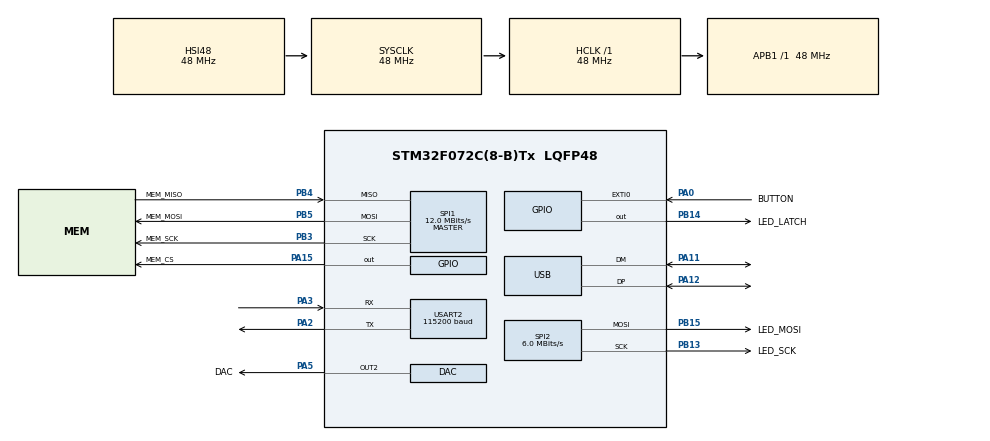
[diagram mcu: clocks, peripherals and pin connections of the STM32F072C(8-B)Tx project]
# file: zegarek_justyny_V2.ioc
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DAC.DAC_Trigger2=DAC_TRIGGER_T6_TRGO
DAC.WaveGeneration2=DISABLE
Dma.DAC_CH2.1.Direction=DMA_MEMORY_TO_PERIPH
Dma.DAC_CH2.1.Instance=DMA1_Channel4
Dma.DAC_CH2.1.MemDataAlignment=DMA_MDATAALIGN_HALFWORD
Dma.DAC_CH2.1.MemInc=DMA_MINC_ENABLE
Dma.DAC_CH2.1.Mode=DMA_CIRCULAR
Dma.DAC_CH2.1.PeriphDataAlignment=DMA_PDATAALIGN_HALFWORD
Dma.DAC_CH2.1.PeriphInc=DMA_PINC_DISABLE
Dma.DAC_CH2.1.Priority=DMA_PRIORITY_VERY_HIGH
Dma.Request0=USART2_RX
Dma.Request1=DAC_CH2
Dma.USART2_RX.0.Direction=DMA_PERIPH_TO_MEMORY
Dma.USART2_RX.0.Instance=DMA1_Channel6
Dma.USART2_RX.0.MemDataAlignment=DMA_MDATAALIGN_BYTE
Dma.USART2_RX.0.MemInc=DMA_MINC_ENABLE
Dma.USART2_RX.0.Mode=DMA_NORMAL
Dma.USART2_RX.0.PeriphDataAlignment=DMA_PDATAALIGN_BYTE
Dma.USART2_RX.0.PeriphInc=DMA_PINC_DISABLE
Dma.USART2_RX.0.Priority=DMA_PRIORITY_HIGH
FATFS._FS_MINIMIZE=1
FATFS._FS_NORTC=1
FATFS._FS_RPATH=1
FATFS._FS_TINY=1
FATFS._MAX_SS=4096
FATFS._MIN_SS=4096
FATFS._NORTC_MDAY=3
FATFS._NORTC_MON=8
FATFS._NORTC_YEAR=1997
FATFS._USE_STRFUNC=1
Mcu.Family=STM32F0
Mcu.Name=STM32F072C(8-B)Tx
Mcu.Package=LQFP48
NVIC.DMA1_Channel4_5_6_7_IRQn=true\:0\:0\:false\:false\:true\:false
NVIC.EXTI0_1_IRQn=true\:0\:0\:false\:false\:true\:true
NVIC.TIM7_IRQn=true\:1\:0\:true\:false\:true\:true
NVIC.USB_IRQn=true\:0\:0\:false\:false\:true\:true
PA0.GPIO_Label=BUTTON
PA0.GPIO_ModeDefaultEXTI=GPIO_MODE_IT_FALLING
PA0.GPIO_PuPd=GPIO_PULLUP
PA0.Signal=GPXTI0
PA11.Mode=Device
PA11.Signal=USB_DM
PA12.Mode=Device
PA12.Signal=USB_DP
PA13.Mode=Serial_Wire
PA13.Signal=SYS_SWDIO
PA14.Mode=Serial_Wire
PA14.Signal=SYS_SWCLK
PA15.GPIO_Label=MEM_CS
PA15.GPIO_Speed=GPIO_SPEED_FREQ_HIGH
PA15.PinState=GPIO_PIN_SET
PA15.Signal=GPIO_Output
PA2.Mode=Asynchronous
PA2.Signal=USART2_TX
PA3.Mode=Asynchronous
PA3.Signal=USART2_RX
PA5.GPIO_Label=DAC
PA5.Signal=COMP_DAC2_group
PB13.GPIO_Label=LED_SCK
PB13.Mode=TX_Only_Simplex_Unidirect_Master
PB13.Signal=SPI2_SCK
PB14.GPIO_Label=LED_LATCH
PB14.Signal=GPIO_Output
PB15.GPIO_Label=LED_MOSI
PB15.Mode=TX_Only_Simplex_Unidirect_Master
PB15.Signal=SPI2_MOSI
PB3.GPIO_Label=MEM_SCK
PB3.Mode=Full_Duplex_Master
PB3.Signal=SPI1_SCK
PB4.GPIO_Label=MEM_MISO
PB4.Mode=Full_Duplex_Master
PB4.Signal=SPI1_MISO
PB5.GPIO_Label=MEM_MOSI
PB5.Mode=Full_Duplex_Master
PB5.Signal=SPI1_MOSI
ProjectManager.HeapSize=0x200
ProjectManager.StackSize=0x400
ProjectManager.TargetToolchain=SW4STM32
RCC.AHBFreq_Value=48000000
RCC.APB1Freq_Value=48000000
RCC.APB1TimFreq_Value=48000000
RCC.HCLKFreq_Value=48000000
RCC.SYSCLKFreq_VALUE=48000000
RCC.SYSCLKSource=RCC_SYSCLKSOURCE_HSI48
RTC.Alarm-Alarm\ A=RTC_ALARM_A
RTC.Format=RTC_FORMAT_BIN
RTC.SynchPrediv=318
SH.COMP_DAC2_group.0=DAC_OUT2,DAC_OUT2
SPI1.BaudRatePrescaler=SPI_BAUDRATEPRESCALER_4
SPI1.CLKPhase=SPI_PHASE_2EDGE
SPI1.CLKPolarity=SPI_POLARITY_HIGH
SPI1.CalculateBaudRate=12.0 MBits/s
SPI1.DataSize=SPI_DATASIZE_8BIT
SPI1.Direction=SPI_DIRECTION_2LINES
SPI1.Mode=SPI_MODE_MASTER
SPI1.VirtualType=VM_MASTER
SPI2.BaudRatePrescaler=SPI_BAUDRATEPRESCALER_8
SPI2.CLKPhase=SPI_PHASE_2EDGE
SPI2.CLKPolarity=SPI_POLARITY_HIGH
SPI2.CalculateBaudRate=6.0 MBits/s
SPI2.DataSize=SPI_DATASIZE_8BIT
SPI2.Direction=SPI_DIRECTION_2LINES
SPI2.Mode=SPI_MODE_MASTER
SPI2.VirtualType=VM_MASTER
TIM6.Period=32768
TIM6.TIM_MasterOutputTrigger=TIM_TRGO_UPDATE
TIM7.Period=210
TIM7.Prescaler=1000
USART2.BaudRate=115200
USART2.VirtualMode-Asynchronous=VM_ASYNC
USART2.WordLength=WORDLENGTH_8B
USB_DEVICE.CLASS_NAME_FS=MSC
USB_DEVICE.MANUFACTURER_STRING=Robert Krauze
USB_DEVICE.MSC_MEDIA_PACKET=4096
USB_DEVICE.PRODUCT_STRING_MSC_FS=Zegarek
USB_DEVICE.VirtualMode=Msc
USB_DEVICE.VirtualModeFS=Msc_FS
VP_FATFS_VS_Generic.Mode=User_defined
VP_RTC_VS_RTC_Activate.Mode=RTC_Enabled
VP_RTC_VS_RTC_Alarm_A_Intern.Mode=Alarm A
VP_RTC_VS_RTC_Calendar.Mode=RTC_Calendar
VP_TIM6_VS_ClockSourceINT.Mode=Enable_Timer
VP_TIM7_VS_ClockSourceINT.Mode=Enable_Timer
VP_USB_DEVICE_VS_USB_DEVICE_MSC_FS.Mode=MSC_FS
board=zegarek_justyny_V2

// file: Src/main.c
/**
  ******************************************************************************
  * @file           : main.c
  * @brief          : Main program body
  ******************************************************************************
  * This notice applies to any and all portions of this file
  * that are not between comment pairs USER CODE BEGIN and
  * USER CODE END. Other portions of this file, whether
  * inserted by the user or by software development tools
  * are owned by their respective copyright owners.
  *
  * Copyright (c) 2018 STMicroelectronics International N.V.
  * All rights reserved.
  *
  * Redistribution and use in source and binary forms, with or without
  * modification, are permitted, provided that the following conditions are met:
  *
  * 1. Redistribution of source code must retain the above copyright notice,
  *    this list of conditions and the following disclaimer.
  * 2. Redistributions in binary form must reproduce the above copyright notice,
  *    this list of conditions and the following disclaimer in the documentation
  *    and/or other materials provided with the distribution.
  * 3. Neither the name of STMicroelectronics nor the names of other
  *    contributors to this software may be used to endorse or promote products
  *    derived from this software without specific written permission.
  * 4. This software, including modifications and/or derivative works of this
  *    software, must execute solely and exclusively on microcontroller or
  *    microprocessor devices manufactured by or for STMicroelectronics.
  * 5. Redistribution and use of this software other than as permitted under
  *    this license is void and will automatically terminate your rights under
  *    this license.
  *
  * THIS SOFTWARE IS PROVIDED BY STMICROELECTRONICS AND CONTRIBUTORS "AS IS"
  * AND ANY EXPRESS, IMPLIED OR STATUTORY WARRANTIES, INCLUDING, BUT NOT
  * LIMITED TO, THE IMPLIED WARRANTIES OF MERCHANTABILITY, FITNESS FOR A
  * PARTICULAR PURPOSE AND NON-INFRINGEMENT OF THIRD PARTY INTELLECTUAL PROPERTY
  * RIGHTS ARE DISCLAIMED TO THE FULLEST EXTENT PERMITTED BY LAW. IN NO EVENT
  * SHALL STMICROELECTRONICS OR CONTRIBUTORS BE LIABLE FOR ANY DIRECT, INDIRECT,
  * INCIDENTAL, SPECIAL, EXEMPLARY, OR CONSEQUENTIAL DAMAGES (INCLUDING, BUT NOT
  * LIMITED TO, PROCUREMENT OF SUBSTITUTE GOODS OR SERVICES; LOSS OF USE, DATA,
  * OR PROFITS; OR BUSINESS INTERRUPTION) HOWEVER CAUSED AND ON ANY THEORY OF
  * LIABILITY, WHETHER IN CONTRACT, STRICT LIABILITY, OR TORT (INCLUDING
  * NEGLIGENCE OR OTHERWISE) ARISING IN ANY WAY OUT OF THE USE OF THIS SOFTWARE,
  * EVEN IF ADVISED OF THE POSSIBILITY OF SUCH DAMAGE.
  *
  ******************************************************************************
  */
#include "main.h"
#include "stm32f0xx_hal.h"
#include "fatfs.h"
#include "usb_device.h"

/* USER CODE BEGIN Includes */
#include "../SW4STM32/zegarek_justyny_V2/Application/User/Led/led.h"
#include "../SW4STM32/zegarek_justyny_V2/Application/User/WiFi/wifi.h"
#include "../SW4STM32/zegarek_justyny_V2/Application/User/Flash_mem/mem_funs.h"
#include "../SW4STM32/zegarek_justyny_V2/Application/User/Scheduler/scheduler.h"
#include "../SW4STM32/zegarek_justyny_V2/Application/User/RTC/rtc.h"
#include "../SW4STM32/zegarek_justyny_V2/Application/User/WAV_player/wav_player.h"
#include "usbd_msc.h"
/* USER CODE END Includes */

DAC_HandleTypeDef hdac;
DMA_HandleTypeDef hdma_dac_ch2;

RTC_HandleTypeDef hrtc;

SPI_HandleTypeDef hspi1;
SPI_HandleTypeDef hspi2;

TIM_HandleTypeDef htim6;
TIM_HandleTypeDef htim7;

UART_HandleTypeDef huart2;
DMA_HandleTypeDef hdma_usart2_rx;

/* USER CODE BEGIN PV */
/* Private variables ---------------------------------------------------------*/
/* USER CODE END PV */

void SystemClock_Config(void);
static void MX_GPIO_Init(void);
static void MX_DMA_Init(void);
static void MX_DAC_Init(void);
static void MX_RTC_Init(void);
static void MX_SPI1_Init(void);
static void MX_SPI2_Init(void);
static void MX_USART2_UART_Init(void);
static void MX_TIM6_Init(void);
static void MX_TIM7_Init(void);

/* USER CODE BEGIN PFP */
/* Private function prototypes -----------------------------------------------*/

/* USER CODE END PFP */

/* USER CODE BEGIN 0 */
//Fiszera 00000111111
/* USER CODE END 0 */

int main(void)
{

  /* MCU Configuration----------------------------------------------------------*/

  /* Reset of all peripherals, Initializes the Flash interface and the Systick. */
  HAL_Init();

  /* Configure the system clock */
  SystemClock_Config();

  /* USER CODE BEGIN SysInit */
  HAL_Delay(1500);
  /* USER CODE END SysInit */

  /* Initialize all configured peripherals */
  MX_GPIO_Init();
  MX_DMA_Init();
  MX_DAC_Init();
  MX_RTC_Init();
  MX_SPI1_Init();
  MX_SPI2_Init();
  MX_USART2_UART_Init();
  MX_FATFS_Init();
  MX_TIM6_Init();
  MX_TIM7_Init();
  /* USER CODE BEGIN 2 */

#if 1
#if 0
  MX_USB_DEVICE_Init();

  	mem_register_SPI(&hspi1);
	mem_init();

#else
	mem_register_SPI(&hspi1);
	mem_init();

	f_forcemount(0);

	wifi_init(&huart2);
	rtc_module_init();

	led_init(&htim7, &hspi2, LED_LATCH_GPIO_Port, LED_LATCH_Pin);

#endif
#endif
  /* USER CODE END 2 */

  /* Infinite loop */
  while (1)
  {

  /* USER CODE BEGIN 3 */
	  scheduler_pool();
  }
  /* USER CODE END 3 */

}

void SystemClock_Config(void)
{

  RCC_OscInitTypeDef RCC_OscInitStruct;
  RCC_ClkInitTypeDef RCC_ClkInitStruct;
  RCC_PeriphCLKInitTypeDef PeriphClkInit;

    /**Initializes the CPU, AHB and APB busses clocks
    */
  RCC_OscInitStruct.OscillatorType = RCC_OSCILLATORTYPE_HSI48|RCC_OSCILLATORTYPE_LSI;
  RCC_OscInitStruct.HSI48State = RCC_HSI48_ON;
  RCC_OscInitStruct.LSIState = RCC_LSI_ON;
  RCC_OscInitStruct.PLL.PLLState = RCC_PLL_NONE;
  if (HAL_RCC_OscConfig(&RCC_OscInitStruct) != HAL_OK)
  {
    _Error_Handler(__FILE__, __LINE__);
  }

    /**Initializes the CPU, AHB and APB busses clocks
    */
  RCC_ClkInitStruct.ClockType = RCC_CLOCKTYPE_HCLK|RCC_CLOCKTYPE_SYSCLK
                              |RCC_CLOCKTYPE_PCLK1;
  RCC_ClkInitStruct.SYSCLKSource = RCC_SYSCLKSOURCE_HSI48;
  RCC_ClkInitStruct.AHBCLKDivider = RCC_SYSCLK_DIV1;
  RCC_ClkInitStruct.APB1CLKDivider = RCC_HCLK_DIV1;

  if (HAL_RCC_ClockConfig(&RCC_ClkInitStruct, FLASH_LATENCY_1) != HAL_OK)
  {
    _Error_Handler(__FILE__, __LINE__);
  }

  PeriphClkInit.PeriphClockSelection = RCC_PERIPHCLK_USB|RCC_PERIPHCLK_USART2
                              |RCC_PERIPHCLK_RTC;
  PeriphClkInit.Usart2ClockSelection = RCC_USART2CLKSOURCE_PCLK1;
  PeriphClkInit.RTCClockSelection = RCC_RTCCLKSOURCE_LSI;
  PeriphClkInit.UsbClockSelection = RCC_USBCLKSOURCE_HSI48;

  if (HAL_RCCEx_PeriphCLKConfig(&PeriphClkInit) != HAL_OK)
  {
    _Error_Handler(__FILE__, __LINE__);
  }

    /**Configure the Systick interrupt time
    */
  HAL_SYSTICK_Config(HAL_RCC_GetHCLKFreq()/1000);

    /**Configure the Systick
    */
  HAL_SYSTICK_CLKSourceConfig(SYSTICK_CLKSOURCE_HCLK);

  /* SysTick_IRQn interrupt configuration */
  HAL_NVIC_SetPriority(SysTick_IRQn, 0, 0);
}

/* DAC init function */
static void MX_DAC_Init(void)
{

  DAC_ChannelConfTypeDef sConfig;

    /**DAC Initialization
    */
  hdac.Instance = DAC;
  if (HAL_DAC_Init(&hdac) != HAL_OK)
  {
    _Error_Handler(__FILE__, __LINE__);
  }

    /**DAC channel OUT2 config
    */
  sConfig.DAC_Trigger = DAC_TRIGGER_T6_TRGO;
  sConfig.DAC_OutputBuffer = DAC_OUTPUTBUFFER_ENABLE;
  if (HAL_DAC_ConfigChannel(&hdac, &sConfig, DAC_CHANNEL_2) != HAL_OK)
  {
    _Error_Handler(__FILE__, __LINE__);
  }

}

/* RTC init function */
static void MX_RTC_Init(void)
{

  RTC_TimeTypeDef sTime;
  RTC_DateTypeDef sDate;
  RTC_AlarmTypeDef sAlarm;

    /**Initialize RTC Only
    */
  hrtc.Instance = RTC;
  hrtc.Init.HourFormat = RTC_HOURFORMAT_24;
  hrtc.Init.AsynchPrediv = 127;
  hrtc.Init.SynchPrediv = 318;
  hrtc.Init.OutPut = RTC_OUTPUT_DISABLE;
  hrtc.Init.OutPutPolarity = RTC_OUTPUT_POLARITY_HIGH;
  hrtc.Init.OutPutType = RTC_OUTPUT_TYPE_OPENDRAIN;
  if (HAL_RTC_Init(&hrtc) != HAL_OK)
  {
    _Error_Handler(__FILE__, __LINE__);
  }

    /**Initialize RTC and set the Time and Date
    */
  sTime.Hours = 0;
  sTime.Minutes = 0;
  sTime.Seconds = 0;
  sTime.DayLightSaving = RTC_DAYLIGHTSAVING_NONE;
  sTime.StoreOperation = RTC_STOREOPERATION_RESET;
  if (HAL_RTC_SetTime(&hrtc, &sTime, RTC_FORMAT_BIN) != HAL_OK)
  {
    _Error_Handler(__FILE__, __LINE__);
  }

  sDate.WeekDay = RTC_WEEKDAY_MONDAY;
  sDate.Month = RTC_MONTH_JANUARY;
  sDate.Date = 1;
  sDate.Year = 0;

  if (HAL_RTC_SetDate(&hrtc, &sDate, RTC_FORMAT_BIN) != HAL_OK)
  {
    _Error_Handler(__FILE__, __LINE__);
  }

    /**Enable the Alarm A
    */
  sAlarm.AlarmTime.Hours = 0;
  sAlarm.AlarmTime.Minutes = 0;
  sAlarm.AlarmTime.Seconds = 0;
  sAlarm.AlarmTime.SubSeconds = 0;
  sAlarm.AlarmTime.DayLightSaving = RTC_DAYLIGHTSAVING_NONE;
  sAlarm.AlarmTime.StoreOperation = RTC_STOREOPERATION_RESET;
  sAlarm.AlarmMask = RTC_ALARMMASK_NONE;
  sAlarm.AlarmSubSecondMask = RTC_ALARMSUBSECONDMASK_ALL;
  sAlarm.AlarmDateWeekDaySel = RTC_ALARMDATEWEEKDAYSEL_DATE;
  sAlarm.AlarmDateWeekDay = 1;
  sAlarm.Alarm = RTC_ALARM_A;
  if (HAL_RTC_SetAlarm(&hrtc, &sAlarm, RTC_FORMAT_BIN) != HAL_OK)
  {
    _Error_Handler(__FILE__, __LINE__);
  }

}

/* SPI1 init function */
static void MX_SPI1_Init(void)
{

  /* SPI1 parameter configuration*/
  hspi1.Instance = SPI1;
  hspi1.Init.Mode = SPI_MODE_MASTER;
  hspi1.Init.Direction = SPI_DIRECTION_2LINES;
  hspi1.Init.DataSize = SPI_DATASIZE_8BIT;
  hspi1.Init.CLKPolarity = SPI_POLARITY_HIGH;
  hspi1.Init.CLKPhase = SPI_PHASE_2EDGE;
  hspi1.Init.NSS = SPI_NSS_SOFT;
  hspi1.Init.BaudRatePrescaler = SPI_BAUDRATEPRESCALER_4;
  hspi1.Init.FirstBit = SPI_FIRSTBIT_MSB;
  hspi1.Init.TIMode = SPI_TIMODE_DISABLE;
  hspi1.Init.CRCCalculation = SPI_CRCCALCULATION_DISABLE;
  hspi1.Init.CRCPolynomial = 7;
  hspi1.Init.CRCLength = SPI_CRC_LENGTH_DATASIZE;
  hspi1.Init.NSSPMode = SPI_NSS_PULSE_DISABLE;
  if (HAL_SPI_Init(&hspi1) != HAL_OK)
  {
    _Error_Handler(__FILE__, __LINE__);
  }

}

/* SPI2 init function */
static void MX_SPI2_Init(void)
{

  /* SPI2 parameter configuration*/
  hspi2.Instance = SPI2;
  hspi2.Init.Mode = SPI_MODE_MASTER;
  hspi2.Init.Direction = SPI_DIRECTION_2LINES;
  hspi2.Init.DataSize = SPI_DATASIZE_8BIT;
  hspi2.Init.CLKPolarity = SPI_POLARITY_HIGH;
  hspi2.Init.CLKPhase = SPI_PHASE_2EDGE;
  hspi2.Init.NSS = SPI_NSS_SOFT;
  hspi2.Init.BaudRatePrescaler = SPI_BAUDRATEPRESCALER_8;
  hspi2.Init.FirstBit = SPI_FIRSTBIT_MSB;
  hspi2.Init.TIMode = SPI_TIMODE_DISABLE;
  hspi2.Init.CRCCalculation = SPI_CRCCALCULATION_DISABLE;
  hspi2.Init.CRCPolynomial = 7;
  hspi2.Init.CRCLength = SPI_CRC_LENGTH_DATASIZE;
  hspi2.Init.NSSPMode = SPI_NSS_PULSE_DISABLE;
  if (HAL_SPI_Init(&hspi2) != HAL_OK)
  {
    _Error_Handler(__FILE__, __LINE__);
  }

}

/* TIM6 init function */
static void MX_TIM6_Init(void)
{

  TIM_MasterConfigTypeDef sMasterConfig;

  htim6.Instance = TIM6;
  htim6.Init.Prescaler = 0;
  htim6.Init.CounterMode = TIM_COUNTERMODE_UP;
  htim6.Init.Period = 32768;
  htim6.Init.AutoReloadPreload = TIM_AUTORELOAD_PRELOAD_DISABLE;
  if (HAL_TIM_Base_Init(&htim6) != HAL_OK)
  {
    _Error_Handler(__FILE__, __LINE__);
  }

  sMasterConfig.MasterOutputTrigger = TIM_TRGO_UPDATE;
  sMasterConfig.MasterSlaveMode = TIM_MASTERSLAVEMODE_DISABLE;
  if (HAL_TIMEx_MasterConfigSynchronization(&htim6, &sMasterConfig) != HAL_OK)
  {
    _Error_Handler(__FILE__, __LINE__);
  }

}

/* TIM7 init function */
static void MX_TIM7_Init(void)
{

  TIM_MasterConfigTypeDef sMasterConfig;

  htim7.Instance = TIM7;
  htim7.Init.Prescaler = 1000;
  htim7.Init.CounterMode = TIM_COUNTERMODE_UP;
  htim7.Init.Period = 300;
  htim7.Init.AutoReloadPreload = TIM_AUTORELOAD_PRELOAD_DISABLE;
  if (HAL_TIM_Base_Init(&htim7) != HAL_OK)
  {
    _Error_Handler(__FILE__, __LINE__);
  }

  sMasterConfig.MasterOutputTrigger = TIM_TRGO_RESET;
  sMasterConfig.MasterSlaveMode = TIM_MASTERSLAVEMODE_DISABLE;
  if (HAL_TIMEx_MasterConfigSynchronization(&htim7, &sMasterConfig) != HAL_OK)
  {
    _Error_Handler(__FILE__, __LINE__);
  }

}

/* USART2 init function */
static void MX_USART2_UART_Init(void)
{

  huart2.Instance = USART2;
  huart2.Init.BaudRate = 115200;
  huart2.Init.WordLength = UART_WORDLENGTH_8B;
  huart2.Init.StopBits = UART_STOPBITS_1;
  huart2.Init.Parity = UART_PARITY_NONE;
  huart2.Init.Mode = UART_MODE_TX_RX;
  huart2.Init.HwFlowCtl = UART_HWCONTROL_NONE;
  huart2.Init.OverSampling = UART_OVERSAMPLING_16;
  huart2.Init.OneBitSampling = UART_ONE_BIT_SAMPLE_DISABLE;
  huart2.AdvancedInit.AdvFeatureInit = UART_ADVFEATURE_NO_INIT;
  if (HAL_UART_Init(&huart2) != HAL_OK)
  {
    _Error_Handler(__FILE__, __LINE__);
  }

}

static void MX_DMA_Init(void)
{
  /* DMA controller clock enable */
  __HAL_RCC_DMA1_CLK_ENABLE();

  /* DMA interrupt init */
  /* DMA1_Channel4_5_6_7_IRQn interrupt configuration */
  HAL_NVIC_SetPriority(DMA1_Channel4_5_6_7_IRQn, 0, 0);
  HAL_NVIC_EnableIRQ(DMA1_Channel4_5_6_7_IRQn);

}

/** Configure pins as
        * Analog
        * Input
        * Output
        * EVENT_OUT
        * EXTI
*/
static void MX_GPIO_Init(void)
{

  GPIO_InitTypeDef GPIO_InitStruct;

  /* GPIO Ports Clock Enable */
  __HAL_RCC_GPIOA_CLK_ENABLE();
  __HAL_RCC_GPIOB_CLK_ENABLE();

  /*Configure GPIO pin Output Level */
  HAL_GPIO_WritePin(SIGNAL_GPIO_Port, SIGNAL_Pin, GPIO_PIN_RESET);

  /*Configure GPIO pin Output Level */
  HAL_GPIO_WritePin(LED_LATCH_GPIO_Port, LED_LATCH_Pin, GPIO_PIN_RESET);

  /*Configure GPIO pin Output Level */
  HAL_GPIO_WritePin(MEM_CS_GPIO_Port, MEM_CS_Pin, GPIO_PIN_SET);

  /*Configure GPIO pin : SIGNAL_Pin */
  GPIO_InitStruct.Pin = SIGNAL_Pin;
  GPIO_InitStruct.Mode = GPIO_MODE_OUTPUT_PP;
  GPIO_InitStruct.Pull = GPIO_NOPULL;
  GPIO_InitStruct.Speed = GPIO_SPEED_FREQ_LOW;
  HAL_GPIO_Init(SIGNAL_GPIO_Port, &GPIO_InitStruct);

  /*Configure GPIO pin : LED_LATCH_Pin */
  GPIO_InitStruct.Pin = LED_LATCH_Pin;
  GPIO_InitStruct.Mode = GPIO_MODE_OUTPUT_PP;
  GPIO_InitStruct.Pull = GPIO_NOPULL;
  GPIO_InitStruct.Speed = GPIO_SPEED_FREQ_LOW;
  HAL_GPIO_Init(LED_LATCH_GPIO_Port, &GPIO_InitStruct);

  /*Configure GPIO pin : MEM_CS_Pin */
  GPIO_InitStruct.Pin = MEM_CS_Pin;
  GPIO_InitStruct.Mode = GPIO_MODE_OUTPUT_PP;
  GPIO_InitStruct.Pull = GPIO_NOPULL;
  GPIO_InitStruct.Speed = GPIO_SPEED_FREQ_HIGH;
  HAL_GPIO_Init(MEM_CS_GPIO_Port, &GPIO_InitStruct);

}

void _Error_Handler(char *file, int line)
{
  while(1)
  {
  }
}

/************************ (C) COPYRIGHT STMicroelectronics *****END OF FILE****/
